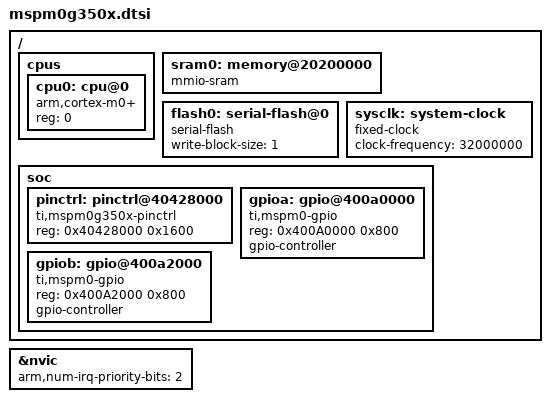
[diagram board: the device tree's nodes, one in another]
/* SPDX-License-Identifier: Apache-2.0 */

#include <arm/armv6-m.dtsi>

#include <zephyr/dt-bindings/gpio/gpio.h>
#include <dt-bindings/pinctrl/ti-mspm0-pinctrl.h>

/ {
	cpus {
		#address-cells = <1>;
		#size-cells = <0>;

		cpu0: cpu@0 {
			compatible = "arm,cortex-m0+";
			reg = <0>;
		};
	};

	sram0: memory@20200000 {
		compatible = "mmio-sram";
	};

	flash0: serial-flash@0 {
		compatible = "serial-flash";
		write-block-size = <1>;
	};

	sysclk: system-clock {
		compatible = "fixed-clock";
		clock-frequency = <32000000>;
		#clock-cells = <0>;
	};

	soc {
		pinctrl: pinctrl@40428000 {
		    compatible = "ti,mspm0g350x-pinctrl";
		    reg = <0x40428000 0x1600>;
		};

		gpioa: gpio@400a0000 {
			compatible = "ti,mspm0-gpio";
			reg = <0x400A0000 0x800>;
			gpio-controller;
			#gpio-cells = <2>;
		};

		gpiob: gpio@400a2000 {
			compatible = "ti,mspm0-gpio";
			reg = <0x400A2000 0x800>;
			gpio-controller;
			#gpio-cells = <2>;
		};
	};
};

&nvic {
	arm,num-irq-priority-bits = <2>;
};
